AUTOSAR XML (schema 4-2-2)
package /STELLANTIS/EPT/COMSWCs
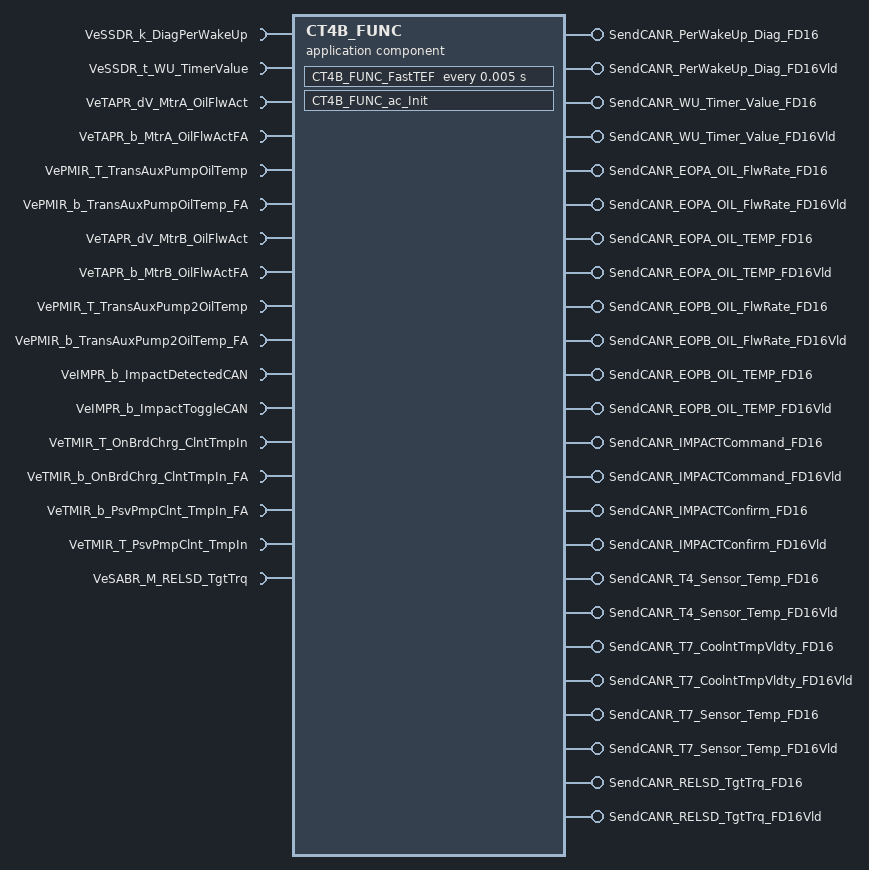
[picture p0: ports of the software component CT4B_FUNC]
  application sw component type CT4B_FUNC
    17 x require port, all with nonqueued-receiver-com-spec{data-element=Value, init-value=0}:
      VeSSDR_k_DiagPerWakeUp: required-interface=VeSSDR_k_DiagPerWakeUp
      VeSSDR_t_WU_TimerValue: required-interface=VeSSDR_t_WU_TimerValue
      VeTAPR_dV_MtrA_OilFlwAct: required-interface=VeTAPR_dV_MtrA_OilFlwAct
      VeTAPR_b_MtrA_OilFlwActFA: required-interface=VeTAPR_b_MtrA_OilFlwActFA
      VePMIR_T_TransAuxPumpOilTemp: required-interface=VePMIR_T_TransAuxPumpOilTemp
      VePMIR_b_TransAuxPumpOilTemp_FA: required-interface=VePMIR_b_TransAuxPumpOilTemp_FA
      VeTAPR_dV_MtrB_OilFlwAct: required-interface=VeTAPR_dV_MtrB_OilFlwAct
      VeTAPR_b_MtrB_OilFlwActFA: required-interface=VeTAPR_b_MtrB_OilFlwActFA
      VePMIR_T_TransAuxPump2OilTemp: required-interface=VePMIR_T_TransAuxPump2OilTemp
      VePMIR_b_TransAuxPump2OilTemp_FA: required-interface=VePMIR_b_TransAuxPump2OilTemp_FA
      VeIMPR_b_ImpactDetectedCAN: required-interface=VeIMPR_b_ImpactDetectedCAN
      VeIMPR_b_ImpactToggleCAN: required-interface=VeIMPR_b_ImpactToggleCAN
      VeTMIR_T_OnBrdChrg_ClntTmpIn: required-interface=VeTMIR_T_OnBrdChrg_ClntTmpIn
      VeTMIR_b_OnBrdChrg_ClntTmpIn_FA: required-interface=VeTMIR_b_OnBrdChrg_ClntTmpIn_FA
      VeTMIR_b_PsvPmpClnt_TmpIn_FA: required-interface=VeTMIR_b_PsvPmpClnt_TmpIn_FA
      VeTMIR_T_PsvPmpClnt_TmpIn: required-interface=VeTMIR_T_PsvPmpClnt_TmpIn
      VeSABR_M_RELSD_TgtTrq: required-interface=VeSABR_M_RELSD_TgtTrq
    24 x provide port:
      SendCANR_PerWakeUp_Diag_FD16: nonqueued-sender-com-spec{data-element=SendCANR_PerWakeUp_Diag_FD16, init-value=0}, provided-interface=SendCANR_PerWakeUp_Diag_FD16
      SendCANR_PerWakeUp_Diag_FD16Vld: nonqueued-sender-com-spec{data-element=SendCANR_PerWakeUp_Diag_FD16Vld, init-value=0}, provided-interface=SendCANR_PerWakeUp_Diag_FD16Vld
      SendCANR_WU_Timer_Value_FD16: nonqueued-sender-com-spec{data-element=SendCANR_WU_Timer_Value_FD16, init-value=0}, provided-interface=SendCANR_WU_Timer_Value_FD16
      SendCANR_WU_Timer_Value_FD16Vld: nonqueued-sender-com-spec{data-element=SendCANR_WU_Timer_Value_FD16Vld, init-value=0}, provided-interface=SendCANR_WU_Timer_Value_FD16Vld
      SendCANR_EOPA_OIL_FlwRate_FD16: nonqueued-sender-com-spec{data-element=SendCANR_EOPA_OIL_FlwRate_FD16, init-value=0}, provided-interface=SendCANR_EOPA_OIL_FlwRate_FD16
      SendCANR_EOPA_OIL_FlwRate_FD16Vld: nonqueued-sender-com-spec{data-element=SendCANR_EOPA_OIL_FlwRate_FD16Vld, init-value=0}, provided-interface=SendCANR_EOPA_OIL_FlwRate_FD16Vld
      SendCANR_EOPA_OIL_TEMP_FD16: nonqueued-sender-com-spec{data-element=SendCANR_EOPA_OIL_TEMP_FD16, init-value=0}, provided-interface=SendCANR_EOPA_OIL_TEMP_FD16
      SendCANR_EOPA_OIL_TEMP_FD16Vld: nonqueued-sender-com-spec{data-element=SendCANR_EOPA_OIL_TEMP_FD16Vld, init-value=0}, provided-interface=SendCANR_EOPA_OIL_TEMP_FD16Vld
      SendCANR_EOPB_OIL_FlwRate_FD16: nonqueued-sender-com-spec{data-element=SendCANR_EOPB_OIL_FlwRate_FD16, init-value=0}, provided-interface=SendCANR_EOPB_OIL_FlwRate_FD16
      SendCANR_EOPB_OIL_FlwRate_FD16Vld: nonqueued-sender-com-spec{data-element=SendCANR_EOPB_OIL_FlwRate_FD16Vld, init-value=0}, provided-interface=SendCANR_EOPB_OIL_FlwRate_FD16Vld
      SendCANR_EOPB_OIL_TEMP_FD16: nonqueued-sender-com-spec{data-element=SendCANR_EOPB_OIL_TEMP_FD16, init-value=0}, provided-interface=SendCANR_EOPB_OIL_TEMP_FD16
      SendCANR_EOPB_OIL_TEMP_FD16Vld: nonqueued-sender-com-spec{data-element=SendCANR_EOPB_OIL_TEMP_FD16Vld, init-value=0}, provided-interface=SendCANR_EOPB_OIL_TEMP_FD16Vld
      SendCANR_IMPACTCommand_FD16: nonqueued-sender-com-spec{data-element=SendCANR_IMPACTCommand_FD16, init-value=0}, provided-interface=SendCANR_IMPACTCommand_FD16
      SendCANR_IMPACTCommand_FD16Vld: nonqueued-sender-com-spec{data-element=SendCANR_IMPACTCommand_FD16Vld, init-value=0}, provided-interface=SendCANR_IMPACTCommand_FD16Vld
      SendCANR_IMPACTConfirm_FD16: nonqueued-sender-com-spec{data-element=SendCANR_IMPACTConfirm_FD16, init-value=0}, provided-interface=SendCANR_IMPACTConfirm_FD16
      SendCANR_IMPACTConfirm_FD16Vld: nonqueued-sender-com-spec{data-element=SendCANR_IMPACTConfirm_FD16Vld, init-value=0}, provided-interface=SendCANR_IMPACTConfirm_FD16Vld
      SendCANR_T4_Sensor_Temp_FD16: nonqueued-sender-com-spec{data-element=SendCANR_T4_Sensor_Temp_FD16, init-value=0}, provided-interface=SendCANR_T4_Sensor_Temp_FD16
      SendCANR_T4_Sensor_Temp_FD16Vld: nonqueued-sender-com-spec{data-element=SendCANR_T4_Sensor_Temp_FD16Vld, init-value=0}, provided-interface=SendCANR_T4_Sensor_Temp_FD16Vld
      SendCANR_T7_CoolntTmpVldty_FD16: nonqueued-sender-com-spec{data-element=SendCANR_T7_CoolntTmpVldty_FD16, init-value=0}, provided-interface=SendCANR_T7_CoolntTmpVldty_FD16
      SendCANR_T7_CoolntTmpVldty_FD16Vld: nonqueued-sender-com-spec{data-element=SendCANR_T7_CoolntTmpVldty_FD16Vld, init-value=0}, provided-interface=SendCANR_T7_CoolntTmpVldty_FD16Vld
      SendCANR_T7_Sensor_Temp_FD16: nonqueued-sender-com-spec{data-element=SendCANR_T7_Sensor_Temp_FD16, init-value=0}, provided-interface=SendCANR_T7_Sensor_Temp_FD16
      SendCANR_T7_Sensor_Temp_FD16Vld: nonqueued-sender-com-spec{data-element=SendCANR_T7_Sensor_Temp_FD16Vld, init-value=0}, provided-interface=SendCANR_T7_Sensor_Temp_FD16Vld
      SendCANR_RELSD_TgtTrq_FD16: nonqueued-sender-com-spec{data-element=SendCANR_RELSD_TgtTrq_FD16, init-value=0}, provided-interface=SendCANR_RELSD_TgtTrq_FD16
      SendCANR_RELSD_TgtTrq_FD16Vld: nonqueued-sender-com-spec{data-element=SendCANR_RELSD_TgtTrq_FD16Vld, init-value=0}, provided-interface=SendCANR_RELSD_TgtTrq_FD16Vld
    behavior IB_CT4B_FUNC: data-type-mapping=[msADTtoIDTMapping, ADTtoIDTMapping], handle-termination-and-restart=NO-SUPPORT
      timing event Event_FastTEF: start-on-event=CT4B_FUNC_FastTEF, period=0.005
      init event Event_CT4B_FUNC_ac_Init: start-on-event=CT4B_FUNC_ac_Init
      runnable CT4B_FUNC_ac_Init
      runnable CT4B_FUNC_FastTEF
        data-receive-point-by-arguments:
          17 x access:
            IN_VeIMPR_b_ImpactDetectedCAN_Value: accessed-variable=VeIMPR_b_ImpactDetectedCAN.Value
            IN_VeIMPR_b_ImpactToggleCAN_Value: accessed-variable=VeIMPR_b_ImpactToggleCAN.Value
            IN_VePMIR_T_TransAuxPump2OilTemp_Value: accessed-variable=VePMIR_T_TransAuxPump2OilTemp.Value
            IN_VePMIR_T_TransAuxPumpOilTemp_Value: accessed-variable=VePMIR_T_TransAuxPumpOilTemp.Value
            IN_VePMIR_b_TransAuxPump2OilTemp_FA_Value: accessed-variable=VePMIR_b_TransAuxPump2OilTemp_FA.Value
            IN_VePMIR_b_TransAuxPumpOilTemp_FA_Value: accessed-variable=VePMIR_b_TransAuxPumpOilTemp_FA.Value
            IN_VeSABR_M_RELSD_TgtTrq_Value: accessed-variable=VeSABR_M_RELSD_TgtTrq.Value
            IN_VeSSDR_k_DiagPerWakeUp_Value: accessed-variable=VeSSDR_k_DiagPerWakeUp.Value
            IN_VeSSDR_t_WU_TimerValue_Value: accessed-variable=VeSSDR_t_WU_TimerValue.Value
            IN_VeTAPR_b_MtrA_OilFlwActFA_Value: accessed-variable=VeTAPR_b_MtrA_OilFlwActFA.Value
            IN_VeTAPR_b_MtrB_OilFlwActFA_Value: accessed-variable=VeTAPR_b_MtrB_OilFlwActFA.Value
            IN_VeTAPR_dV_MtrA_OilFlwAct_Value: accessed-variable=VeTAPR_dV_MtrA_OilFlwAct.Value
            IN_VeTAPR_dV_MtrB_OilFlwAct_Value: accessed-variable=VeTAPR_dV_MtrB_OilFlwAct.Value
            IN_VeTMIR_T_OnBrdChrg_ClntTmpIn_Value: accessed-variable=VeTMIR_T_OnBrdChrg_ClntTmpIn.Value
            IN_VeTMIR_T_PsvPmpClnt_TmpIn_Value: accessed-variable=VeTMIR_T_PsvPmpClnt_TmpIn.Value
            IN_VeTMIR_b_OnBrdChrg_ClntTmpIn_FA_Value: accessed-variable=VeTMIR_b_OnBrdChrg_ClntTmpIn_FA.Value
            IN_VeTMIR_b_PsvPmpClnt_TmpIn_FA_Value: accessed-variable=VeTMIR_b_PsvPmpClnt_TmpIn_FA.Value
        data-send-points:
          24 x access:
            OUT_SendCANR_PerWakeUp_Diag_FD16_SendCANR_PerWakeUp_Diag_FD16: accessed-variable=SendCANR_PerWakeUp_Diag_FD16.SendCANR_PerWakeUp_Diag_FD16
            OUT_SendCANR_PerWakeUp_Diag_FD16Vld_SendCANR_PerWakeUp_Diag_FD16Vld: accessed-variable=SendCANR_PerWakeUp_Diag_FD16Vld.SendCANR_PerWakeUp_Diag_FD16Vld
            OUT_SendCANR_WU_Timer_Value_FD16_SendCANR_WU_Timer_Value_FD16: accessed-variable=SendCANR_WU_Timer_Value_FD16.SendCANR_WU_Timer_Value_FD16
            OUT_SendCANR_WU_Timer_Value_FD16Vld_SendCANR_WU_Timer_Value_FD16Vld: accessed-variable=SendCANR_WU_Timer_Value_FD16Vld.SendCANR_WU_Timer_Value_FD16Vld
            OUT_SendCANR_EOPA_OIL_FlwRate_FD16_SendCANR_EOPA_OIL_FlwRate_FD16: accessed-variable=SendCANR_EOPA_OIL_FlwRate_FD16.SendCANR_EOPA_OIL_FlwRate_FD16
            OUT_SendCANR_EOPA_OIL_FlwRate_FD16Vld_SendCANR_EOPA_OIL_FlwRate_FD16Vld: accessed-variable=SendCANR_EOPA_OIL_FlwRate_FD16Vld.SendCANR_EOPA_OIL_FlwRate_FD16Vld
            OUT_SendCANR_EOPA_OIL_TEMP_FD16_SendCANR_EOPA_OIL_TEMP_FD16: accessed-variable=SendCANR_EOPA_OIL_TEMP_FD16.SendCANR_EOPA_OIL_TEMP_FD16
            OUT_SendCANR_EOPA_OIL_TEMP_FD16Vld_SendCANR_EOPA_OIL_TEMP_FD16Vld: accessed-variable=SendCANR_EOPA_OIL_TEMP_FD16Vld.SendCANR_EOPA_OIL_TEMP_FD16Vld
            OUT_SendCANR_EOPB_OIL_FlwRate_FD16_SendCANR_EOPB_OIL_FlwRate_FD16: accessed-variable=SendCANR_EOPB_OIL_FlwRate_FD16.SendCANR_EOPB_OIL_FlwRate_FD16
            OUT_SendCANR_EOPB_OIL_FlwRate_FD16Vld_SendCANR_EOPB_OIL_FlwRate_FD16Vld: accessed-variable=SendCANR_EOPB_OIL_FlwRate_FD16Vld.SendCANR_EOPB_OIL_FlwRate_FD16Vld
            OUT_SendCANR_EOPB_OIL_TEMP_FD16_SendCANR_EOPB_OIL_TEMP_FD16: accessed-variable=SendCANR_EOPB_OIL_TEMP_FD16.SendCANR_EOPB_OIL_TEMP_FD16
            OUT_SendCANR_EOPB_OIL_TEMP_FD16Vld_SendCANR_EOPB_OIL_TEMP_FD16Vld: accessed-variable=SendCANR_EOPB_OIL_TEMP_FD16Vld.SendCANR_EOPB_OIL_TEMP_FD16Vld
            OUT_SendCANR_IMPACTCommand_FD16_SendCANR_IMPACTCommand_FD16: accessed-variable=SendCANR_IMPACTCommand_FD16.SendCANR_IMPACTCommand_FD16
            OUT_SendCANR_IMPACTCommand_FD16Vld_SendCANR_IMPACTCommand_FD16Vld: accessed-variable=SendCANR_IMPACTCommand_FD16Vld.SendCANR_IMPACTCommand_FD16Vld
            OUT_SendCANR_IMPACTConfirm_FD16_SendCANR_IMPACTConfirm_FD16: accessed-variable=SendCANR_IMPACTConfirm_FD16.SendCANR_IMPACTConfirm_FD16
            OUT_SendCANR_IMPACTConfirm_FD16Vld_SendCANR_IMPACTConfirm_FD16Vld: accessed-variable=SendCANR_IMPACTConfirm_FD16Vld.SendCANR_IMPACTConfirm_FD16Vld
            OUT_SendCANR_T4_Sensor_Temp_FD16_SendCANR_T4_Sensor_Temp_FD16: accessed-variable=SendCANR_T4_Sensor_Temp_FD16.SendCANR_T4_Sensor_Temp_FD16
            OUT_SendCANR_T4_Sensor_Temp_FD16Vld_SendCANR_T4_Sensor_Temp_FD16Vld: accessed-variable=SendCANR_T4_Sensor_Temp_FD16Vld.SendCANR_T4_Sensor_Temp_FD16Vld
            OUT_SendCANR_T7_CoolntTmpVldty_FD16_SendCANR_T7_CoolntTmpVldty_FD16: accessed-variable=SendCANR_T7_CoolntTmpVldty_FD16.SendCANR_T7_CoolntTmpVldty_FD16
            OUT_SendCANR_T7_CoolntTmpVldty_FD16Vld_SendCANR_T7_CoolntTmpVldty_FD16Vld: accessed-variable=SendCANR_T7_CoolntTmpVldty_FD16Vld.SendCANR_T7_CoolntTmpVldty_FD16Vld
            OUT_SendCANR_T7_Sensor_Temp_FD16_SendCANR_T7_Sensor_Temp_FD16: accessed-variable=SendCANR_T7_Sensor_Temp_FD16.SendCANR_T7_Sensor_Temp_FD16
            OUT_SendCANR_T7_Sensor_Temp_FD16Vld_SendCANR_T7_Sensor_Temp_FD16Vld: accessed-variable=SendCANR_T7_Sensor_Temp_FD16Vld.SendCANR_T7_Sensor_Temp_FD16Vld
            OUT_SendCANR_RELSD_TgtTrq_FD16_SendCANR_RELSD_TgtTrq_FD16: accessed-variable=SendCANR_RELSD_TgtTrq_FD16.SendCANR_RELSD_TgtTrq_FD16
            OUT_SendCANR_RELSD_TgtTrq_FD16Vld_SendCANR_RELSD_TgtTrq_FD16Vld: accessed-variable=SendCANR_RELSD_TgtTrq_FD16Vld.SendCANR_RELSD_TgtTrq_FD16Vld
